# STM32F765BGT6 register map
File version: 1.0
Registers are 32-bit, access not given, reset 0x0 unless marked. A register's access mark holds for its fields unless they carry their own. Offsets are from the block's base; [hi:lo] are bit positions; {n}, {i} and the like mark numbered series.

## DFSDM1
Base 0x40017400
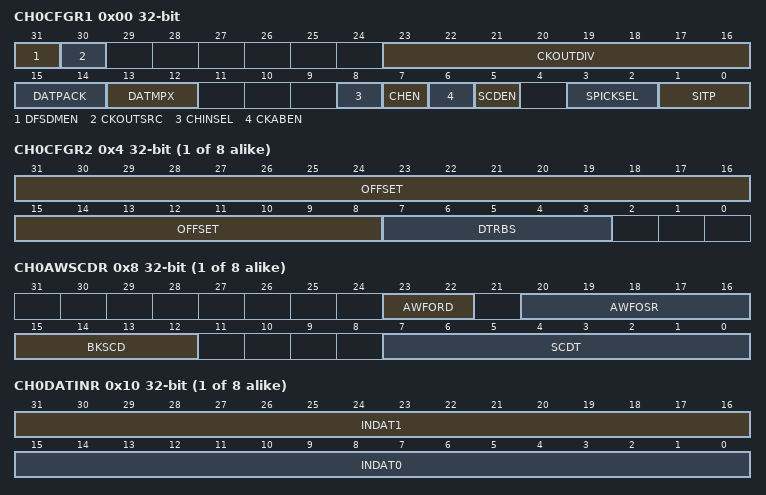
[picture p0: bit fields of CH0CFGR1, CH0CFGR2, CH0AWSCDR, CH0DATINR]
0x00 CH0CFGR1
  [31] DFSDMEN, [30] CKOUTSRC, [23:16] CKOUTDIV, [15:14] DATPACK, [13:12] DATMPX, [8] CHINSEL, [7] CHEN, [6] CKABEN, [5] SCDEN, [3:2] SPICKSEL, [1:0] SITP
{0x4+0x20*i} CH{i}CFGR2 (i=0..7)
  [31:8] OFFSET, [7:3] DTRBS
{0x8+0x20*i} CH{i}AWSCDR (i=0..7)
  [23:22] AWFORD, [20:16] AWFOSR, [15:12] BKSCD, [7:0] SCDT
{0xC+0x20*i} CH{i}WDATR (i=0..7)
  [15:0] WDATA
{0x10+0x20*i} CH{i}DATINR (i=0..7)
  [31:16] INDAT1, [15:0] INDAT0
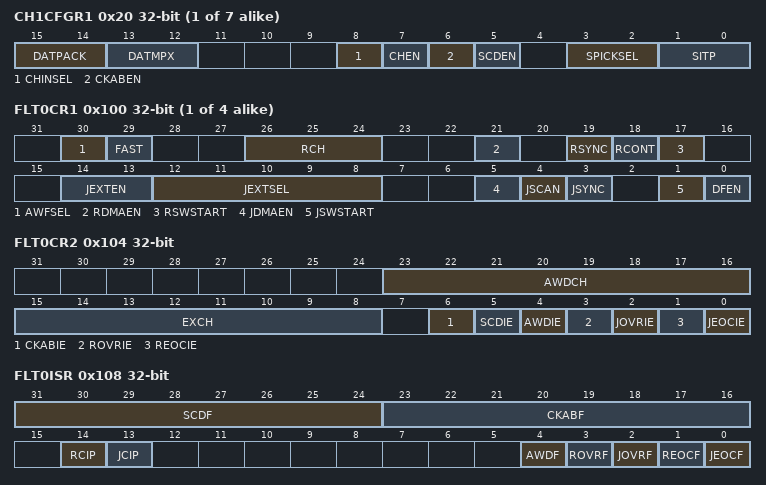
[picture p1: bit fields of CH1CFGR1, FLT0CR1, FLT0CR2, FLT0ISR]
{0x0+0x20*i} CH{i}CFGR1 (i=1..7)
  [15:14] DATPACK, [13:12] DATMPX, [8] CHINSEL, [7] CHEN, [6] CKABEN, [5] SCDEN, [3:2] SPICKSEL, [1:0] SITP
{0x100+0x80*i} FLT{i}CR1 (i=0..3)
  [30] AWFSEL, [29] FAST, [26:24] RCH, [21] RDMAEN, [19] RSYNC, [18] RCONT, [17] RSWSTART, [14:13] JEXTEN, [12:8] JEXTSEL, [5] JDMAEN, [4] JSCAN, [3] JSYNC, [1] JSWSTART, [0] DFEN
0x104 FLT0CR2
  [23:16] AWDCH, [15:8] EXCH, [6] CKABIE, [5] SCDIE, [4] AWDIE, [3] ROVRIE, [2] JOVRIE, [1] REOCIE, [0] JEOCIE
0x108 FLT0ISR
  [31:24] SCDF, [23:16] CKABF, [14] RCIP, [13] JCIP, [4] AWDF, [3] ROVRF, [2] JOVRF, [1] REOCF, [0] JEOCF
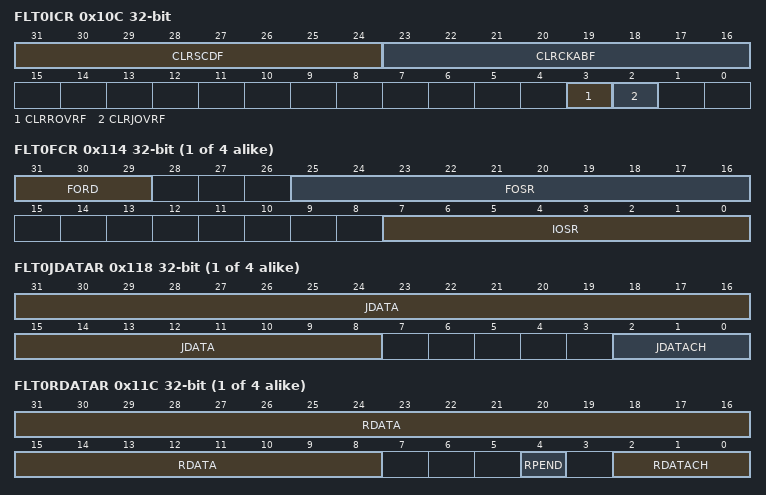
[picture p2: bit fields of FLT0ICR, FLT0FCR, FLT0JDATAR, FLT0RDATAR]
0x10C FLT0ICR
  [31:24] CLRSCDF, [23:16] CLRCKABF, [3] CLRROVRF, [2] CLRJOVRF
{0x110+0x80*i} FLT{i}JCHGR (i=0..3)
  [7:0] JCHG
{0x114+0x80*i} FLT{i}FCR (i=0..3)
  [31:29] FORD, [25:16] FOSR, [7:0] IOSR
{0x118+0x80*i} FLT{i}JDATAR (i=0..3)
  [31:8] JDATA, [2:0] JDATACH
{0x11C+0x80*i} FLT{i}RDATAR (i=0..3)
  [31:8] RDATA, [4] RPEND, [2:0] RDATACH
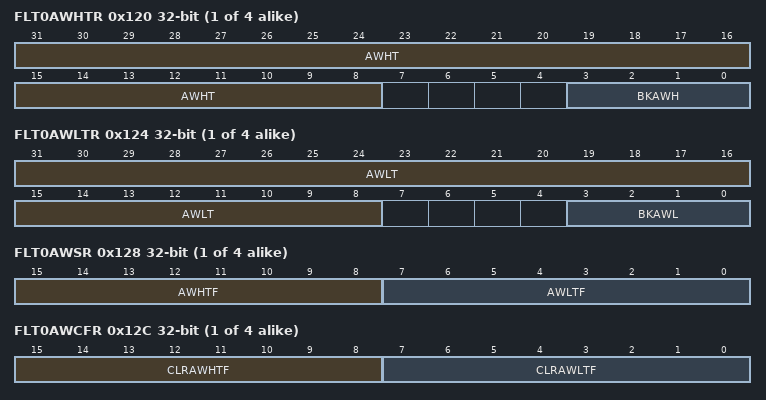
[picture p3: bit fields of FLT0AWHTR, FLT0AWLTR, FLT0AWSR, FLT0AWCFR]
{0x120+0x80*i} FLT{i}AWHTR (i=0..3)
  [31:8] AWHT, [3:0] BKAWH
{0x124+0x80*i} FLT{i}AWLTR (i=0..3)
  [31:8] AWLT, [3:0] BKAWL
{0x128+0x80*i} FLT{i}AWSR (i=0..3)
  [15:8] AWHTF, [7:0] AWLTF
{0x12C+0x80*i} FLT{i}AWCFR (i=0..3)
  [15:8] CLRAWHTF, [7:0] CLRAWLTF
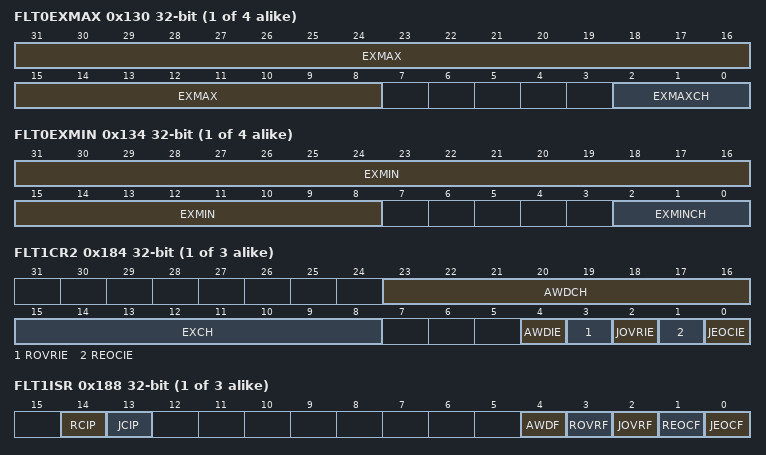
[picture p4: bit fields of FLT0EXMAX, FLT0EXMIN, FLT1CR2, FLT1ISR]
{0x130+0x80*i} FLT{i}EXMAX (i=0..3)
  [31:8] EXMAX, [2:0] EXMAXCH
{0x134+0x80*i} FLT{i}EXMIN (i=0..3)
  [31:8] EXMIN, [2:0] EXMINCH
{0x138+0x80*i} FLT{i}CNVTIMR (i=0..3)
  [31:4] CNVCNT
{0x104+0x80*i} FLT{i}CR2 (i=1..3)
  [23:16] AWDCH, [15:8] EXCH, [4] AWDIE, [3] ROVRIE, [2] JOVRIE, [1] REOCIE, [0] JEOCIE
{0x108+0x80*i} FLT{i}ISR (i=1..3)
  [14] RCIP, [13] JCIP, [4] AWDF, [3] ROVRF, [2] JOVRF, [1] REOCF, [0] JEOCF
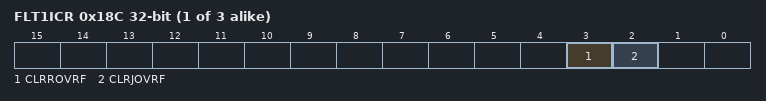
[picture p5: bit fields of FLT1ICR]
{0x10C+0x80*i} FLT{i}ICR (i=1..3)
  [3] CLRROVRF, [2] CLRJOVRF

## MDIOS
Base 0x40017800
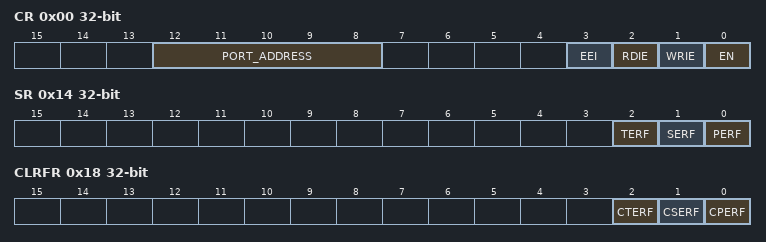
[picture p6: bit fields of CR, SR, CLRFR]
0x00 CR
  [12:8] PORT_ADDRESS, [3] EEI, [2] RDIE, [1] WRIE, [0] EN
0x04 WRFR
  [31:0] WRF
0x08 CWRFR
  [31:0] CWRF
0x0C RDFR
  [31:0] RDF
0x10 CRDFR
  [31:0] CRDF
0x14 SR
  [2] TERF, [1] SERF, [0] PERF
0x18 CLRFR
  [2] CTERF, [1] CSERF, [0] CPERF
0x100 DINR0
  [15:0] DIN0
0x104 DINR1
  [15:0] DIN1
0x17C DINR31
  [15:0] DIN31
0x180 DOUTR0
  [15:0] DOUT0
0x184 DOUTR1
  [15:0] DOUT1
0x1FC DOUTR31
  [15:0] DOUT31

## GPIOA
Base 0x40020000
Same registers: GPIOB 0x40020400
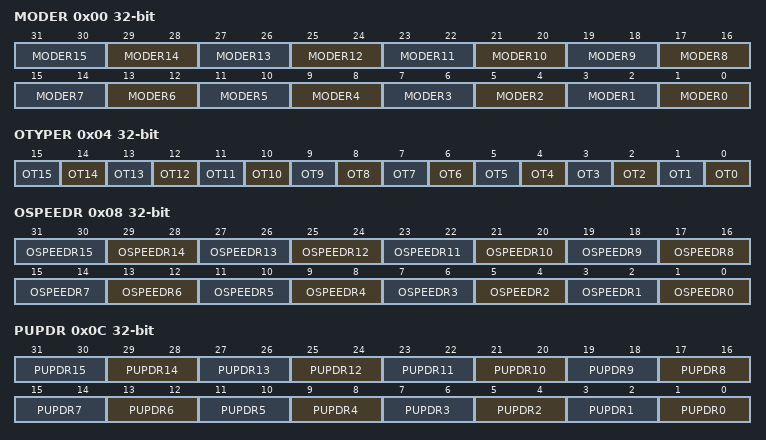
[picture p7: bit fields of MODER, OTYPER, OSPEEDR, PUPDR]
0x00 MODER
  [2n+1:2n] MODER{n} (n=0..15)
0x04 OTYPER
  [n] OT{n} (n=0..15)
0x08 OSPEEDR
  [2n+1:2n] OSPEEDR{n} (n=0..15)
0x0C PUPDR
  [2n+1:2n] PUPDR{n} (n=0..15)
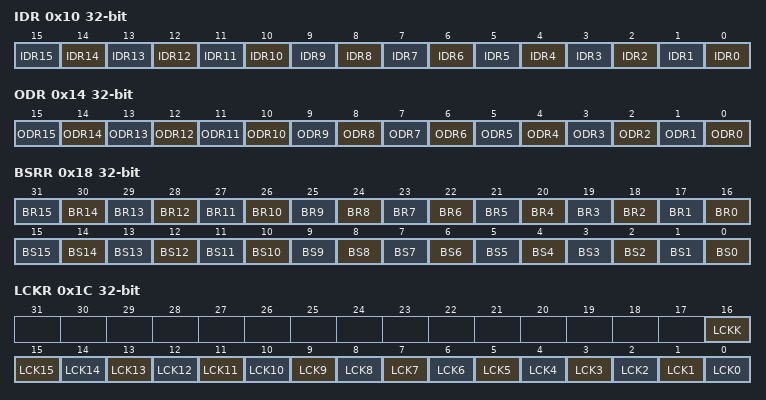
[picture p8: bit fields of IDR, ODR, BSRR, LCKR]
0x10 IDR
  [n] IDR{n} (n=0..15)
0x14 ODR
  [n] ODR{n} (n=0..15)
0x18 BSRR
  [n+16] BR{n} (n=0..15), [n] BS{n} (n=0..15)
0x1C LCKR
  [16] LCKK, [n] LCK{n} (n=0..15)
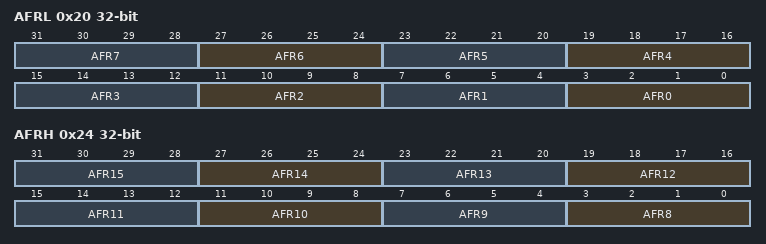
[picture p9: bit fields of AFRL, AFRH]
0x20 AFRL
  [4n+3:4n] AFR{n} (n=0..7)
0x24 AFRH
  [4n-29:4n-32] AFR{n} (n=8..15)

## GPIOC
Base 0x40020800
Registers as GPIOA, without PUPDR.

## GPIOD
Base 0x40020C00
Registers as GPIOA, without PUPDR.

## GPIOE
Base 0x40021000
Registers as GPIOA, without PUPDR.

## GPIOF
Base 0x40021400
Registers as GPIOA, without PUPDR.

## GPIOG
Base 0x40021800
Registers as GPIOA, without PUPDR.

## GPIOH
Base 0x40021C00
Registers as GPIOA, without PUPDR.

## GPIOI
Base 0x40022000
Registers as GPIOA, without PUPDR.

## GPIOJ
Base 0x40022400
Registers as GPIOA, without PUPDR.

## GPIOK
Base 0x40022800
Registers as GPIOA, without PUPDR.
